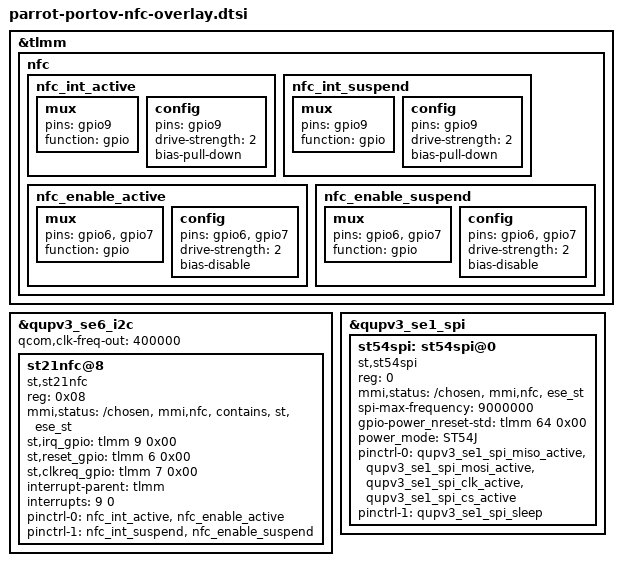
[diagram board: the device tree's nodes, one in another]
&tlmm {
	nfc {
		nfc_int_active: nfc_int_active {
			/* active state */
			mux {
				/* NFC Read Interrupt */
				pins = "gpio9";
				function = "gpio";
			};

			config {
				pins = "gpio9";
				drive-strength = <2>; /* 2 MA */
				bias-pull-down;
			};
		};

		nfc_int_suspend: nfc_int_suspend {
			/* sleep state */
			mux {
				/* NFC Read Interrupt */
				pins = "gpio9";
				function = "gpio";
			};

			config {
				pins = "gpio9";
				drive-strength = <2>; /* 2 MA */
				bias-pull-down;
			};
		};

		nfc_enable_active: nfc_enable_active {
			mux {
				/* Enable, Firmware and Clock request gpios */
				pins = "gpio6", "gpio7";
				function = "gpio";
			};

			config {
				pins = "gpio6", "gpio7";
				drive-strength = <2>; /* 2 MA */
				bias-disable;
			};
		};

		nfc_enable_suspend: nfc_enable_suspend {
			mux {
				pins = "gpio6", "gpio7";
				function = "gpio";
			};

			config {
				pins = "gpio6", "gpio7";
				drive-strength = <2>; /* 2 MA */
				bias-disable;
			};
		};
	};
};

&qupv3_se6_i2c {
	status = "ok";
	qcom,clk-freq-out = <400000>;
	#address-cells = <1>;
	#size-cells = <0>;
	st21nfc@8 {
		compatible = "st,st21nfc";
		reg = <0x08>;
		mmi,status = "/chosen","mmi,nfc","contains","st","ese_st";
		st,irq_gpio = <&tlmm 9 0x00>;
		st,reset_gpio = <&tlmm 6 0x00>;
		st,clkreq_gpio = <&tlmm 7 0x00>;
		interrupt-parent = <&tlmm>;
		interrupts = <9 0>;
		interrupt-names = "nfc_irq";
		pinctrl-names = "nfc_active", "nfc_suspend";
		pinctrl-0 = <&nfc_int_active &nfc_enable_active>;
		pinctrl-1 = <&nfc_int_suspend &nfc_enable_suspend>;
	};
};


&qupv3_se1_spi {
	status = "okay";
	st54spi: st54spi@0 {
		compatible = "st,st54spi";
		reg = <0>;
		mmi,status = "/chosen","mmi,nfc","ese_st";
		spi-max-frequency = <9000000>;
		/* gpio used as SE_PWR_REQ or SE_nRESET */
		gpio-power_nreset-std = <&tlmm 64 0x00>;
		/* Power management mode: none, ST54H (default), ST54J */
		power_mode = "ST54J";
		pinctrl-names = "spi_active", "spi_sleep";
		pinctrl-0 = <&qupv3_se1_spi_miso_active &qupv3_se1_spi_mosi_active &qupv3_se1_spi_clk_active &qupv3_se1_spi_cs_active>;
		pinctrl-1 = <&qupv3_se1_spi_sleep>;
		status = "okay";
	};
};

